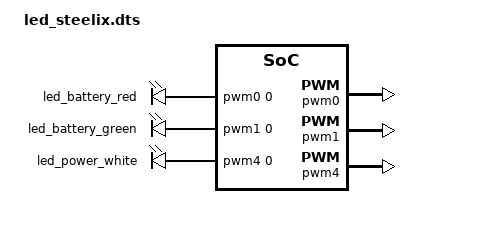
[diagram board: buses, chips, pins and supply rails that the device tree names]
/* Copyright 2022 The ChromiumOS Authors
 * Use of this source code is governed by a BSD-style license that can be
 * found in the LICENSE file.
 */

/ {
	pwmleds {
		compatible = "pwm-leds";
		led_battery_red: ec_led1_odl {
			pwms = <&pwm0 0 PWM_HZ(100) PWM_POLARITY_INVERTED>;
		};
		led_battery_green: ec_led2_odl {
			pwms = <&pwm1 0 PWM_HZ(100) PWM_POLARITY_INVERTED>;
		};
		led_power_white: ec_led3_odl {
			pwms = <&pwm4 0 PWM_HZ(100) PWM_POLARITY_INVERTED>;
		};
	};
};

/* Red LED */
&pwm0_gpc3 {
	drive-open-drain;
};

&pwm0 {
	status = "okay";
	clock-bus = "NPCX_CLOCK_BUS_LFCLK";
	pinctrl-0 = <&pwm0_gpc3>;
	pinctrl-names = "default";
};

/* Green LED */
&pwm1_gpc2 {
	drive-open-drain;
};

&pwm1 {
	status = "okay";
	clock-bus = "NPCX_CLOCK_BUS_LFCLK";
	pinctrl-0 = <&pwm1_gpc2>;
	pinctrl-names = "default";
};

/* White LED */
&pwm4_gpb6 {
	drive-open-drain;
};

&pwm4 {
	status = "okay";
	clock-bus = "NPCX_CLOCK_BUS_LFCLK";
	pinctrl-0 = <&pwm4_gpb6>;
	pinctrl-names = "default";
};
